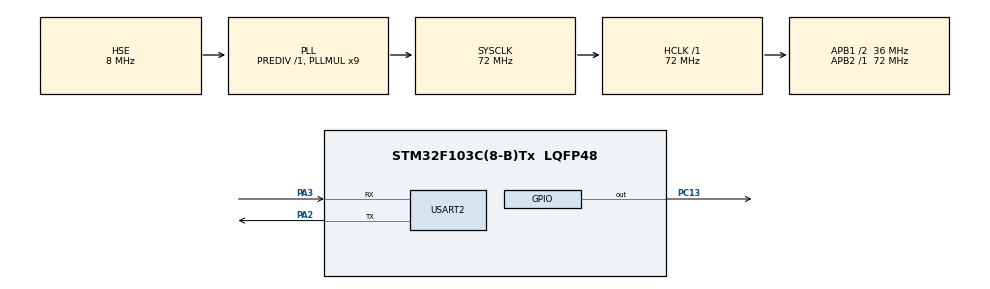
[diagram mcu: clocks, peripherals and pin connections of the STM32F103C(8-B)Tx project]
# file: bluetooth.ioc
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Mcu.Family=STM32F1
Mcu.Name=STM32F103C(8-B)Tx
Mcu.Package=LQFP48
NVIC.PriorityGroup=NVIC_PRIORITYGROUP_4
NVIC.TIM2_IRQn=true\:0\:0\:false\:false\:true\:true\:true\:true
NVIC.USART2_IRQn=true\:0\:0\:false\:false\:true\:true\:true\:true
PA13.Mode=Serial_Wire
PA13.Signal=SYS_JTMS-SWDIO
PA14.Mode=Serial_Wire
PA14.Signal=SYS_JTCK-SWCLK
PA2.Mode=Asynchronous
PA2.Signal=USART2_TX
PA3.Mode=Asynchronous
PA3.Signal=USART2_RX
PC13-TAMPER-RTC.Signal=GPIO_Output
PD0-OSC_IN.Mode=HSE-External-Oscillator
PD0-OSC_IN.Signal=RCC_OSC_IN
PD1-OSC_OUT.Mode=HSE-External-Oscillator
PD1-OSC_OUT.Signal=RCC_OSC_OUT
ProjectManager.HeapSize=0x200
ProjectManager.StackSize=0x400
ProjectManager.TargetToolchain=MDK-ARM V5.32
RCC.AHBFreq_Value=72000000
RCC.APB1CLKDivider=RCC_HCLK_DIV2
RCC.APB1Freq_Value=36000000
RCC.APB1TimFreq_Value=72000000
RCC.APB2Freq_Value=72000000
RCC.APB2TimFreq_Value=72000000
RCC.HCLKFreq_Value=72000000
RCC.PLLMUL=RCC_PLL_MUL9
RCC.PLLSourceVirtual=RCC_PLLSOURCE_HSE
RCC.SYSCLKFreq_VALUE=72000000
RCC.SYSCLKSource=RCC_SYSCLKSOURCE_PLLCLK
RCC.USBFreq_Value=72000000
TIM2.Period=4000
TIM2.Prescaler=35999
TIM2.TIM_MasterOutputTrigger=TIM_TRGO_UPDATE
USART2.VirtualMode=VM_ASYNC
VP_TIM2_VS_ClockSourceINT.Mode=Internal
board=custom

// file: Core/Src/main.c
/* USER CODE BEGIN Header */
/**
  ******************************************************************************
  * @file           : main.c
  * @brief          : Main program body
  ******************************************************************************
  * @attention
  *
  * Copyright (c) 2025 STMicroelectronics.
  * All rights reserved.
  *
  * This software is licensed under terms that can be found in the LICENSE file
  * in the root directory of this software component.
  * If no LICENSE file comes with this software, it is provided AS-IS.
  *
  ******************************************************************************
  */
/* USER CODE END Header */
#include "main.h"

/* USER CODE BEGIN Includes */
#include <string.h>
/* USER CODE END Includes */

TIM_HandleTypeDef htim2;

UART_HandleTypeDef huart2;

/* USER CODE BEGIN PV */
char str1[60] ={0};
typedef struct USART_prop{
	uint8_t usart_buf[60];
	uint8_t usart_cnt;
	uint8_t is_tcp_connect;
	uint8_t is_text;
} USART_prop_ptr;
USART_prop_ptr usartprop;
char *str2[] =
{
	"String1\r\n",
	"String2\r\n",
	"String3\r\n",
	"String4\r\n",
	"String5\r\n"
};
/* USER CODE END PV */

void SystemClock_Config(void);
static void MX_GPIO_Init(void);
static void MX_TIM2_Init(void);
static void MX_USART2_UART_Init(void);

/* USER CODE BEGIN 0 */
void string_parse(char* buf_str){
	HAL_UART_Transmit(&huart2, (uint8_t*)buf_str, strlen(buf_str), 0x1000);
	HAL_GPIO_TogglePin(GPIOA, GPIO_PIN_13);
}
void UART2_RxCpltCallback(void){
	uint8_t b;
	b = str1[0];
	if (usartprop.usart_cnt>59)
	{
		usartprop.usart_cnt=0;

		HAL_UART_Receive_IT(&huart2, (uint8_t*)str1, 1);
		return;
	}
	usartprop.usart_buf[usartprop.usart_cnt] = b;
	if (b==0x0A)
	{
		usartprop.usart_buf[usartprop.usart_cnt+1] = 0;

		string_parse((char*)usartprop.usart_buf);
		usartprop.usart_cnt=0;

		HAL_UART_Receive_IT(&huart2, (uint8_t*)str1, 1);
		return;
	}
	usartprop.usart_cnt++;
	HAL_UART_Receive_IT(&huart2, (uint8_t*)str1, 1);
}
/* USER CODE END 0 */

int main(void)
{

  /* MCU Configuration--------------------------------------------------------*/

  /* Reset of all peripherals, Initializes the Flash interface and the Systick. */
  HAL_Init();

  /* Configure the system clock */
  SystemClock_Config();

  /* Initialize all configured peripherals */
  MX_GPIO_Init();
  MX_TIM2_Init();
  MX_USART2_UART_Init();
  /* USER CODE BEGIN 2 */
HAL_UART_Receive_IT(&huart2, (uint8_t*)str1, 1);
HAL_TIM_Base_Start_IT(&htim2);
  /* USER CODE END 2 */

  /* Infinite loop */
  while (1)
  {

  }
}

void SystemClock_Config(void)
{
  RCC_OscInitTypeDef RCC_OscInitStruct = {0};
  RCC_ClkInitTypeDef RCC_ClkInitStruct = {0};

  /** Initializes the RCC Oscillators according to the specified parameters
  * in the RCC_OscInitTypeDef structure.
  */
  RCC_OscInitStruct.OscillatorType = RCC_OSCILLATORTYPE_HSE;
  RCC_OscInitStruct.HSEState = RCC_HSE_ON;
  RCC_OscInitStruct.HSEPredivValue = RCC_HSE_PREDIV_DIV1;
  RCC_OscInitStruct.HSIState = RCC_HSI_ON;
  RCC_OscInitStruct.PLL.PLLState = RCC_PLL_ON;
  RCC_OscInitStruct.PLL.PLLSource = RCC_PLLSOURCE_HSE;
  RCC_OscInitStruct.PLL.PLLMUL = RCC_PLL_MUL9;
  if (HAL_RCC_OscConfig(&RCC_OscInitStruct) != HAL_OK)
  {
    Error_Handler();
  }

  /** Initializes the CPU, AHB and APB buses clocks
  */
  RCC_ClkInitStruct.ClockType = RCC_CLOCKTYPE_HCLK|RCC_CLOCKTYPE_SYSCLK
                              |RCC_CLOCKTYPE_PCLK1|RCC_CLOCKTYPE_PCLK2;
  RCC_ClkInitStruct.SYSCLKSource = RCC_SYSCLKSOURCE_PLLCLK;
  RCC_ClkInitStruct.AHBCLKDivider = RCC_SYSCLK_DIV1;
  RCC_ClkInitStruct.APB1CLKDivider = RCC_HCLK_DIV2;
  RCC_ClkInitStruct.APB2CLKDivider = RCC_HCLK_DIV1;

  if (HAL_RCC_ClockConfig(&RCC_ClkInitStruct, FLASH_LATENCY_2) != HAL_OK)
  {
    Error_Handler();
  }
}

static void MX_TIM2_Init(void)
{

  TIM_ClockConfigTypeDef sClockSourceConfig = {0};
  TIM_MasterConfigTypeDef sMasterConfig = {0};

  htim2.Instance = TIM2;
  htim2.Init.Prescaler = 35999;
  htim2.Init.CounterMode = TIM_COUNTERMODE_UP;
  htim2.Init.Period = 4000;
  htim2.Init.ClockDivision = TIM_CLOCKDIVISION_DIV1;
  htim2.Init.AutoReloadPreload = TIM_AUTORELOAD_PRELOAD_DISABLE;
  if (HAL_TIM_Base_Init(&htim2) != HAL_OK)
  {
    Error_Handler();
  }
  sClockSourceConfig.ClockSource = TIM_CLOCKSOURCE_INTERNAL;
  if (HAL_TIM_ConfigClockSource(&htim2, &sClockSourceConfig) != HAL_OK)
  {
    Error_Handler();
  }
  sMasterConfig.MasterOutputTrigger = TIM_TRGO_UPDATE;
  sMasterConfig.MasterSlaveMode = TIM_MASTERSLAVEMODE_DISABLE;
  if (HAL_TIMEx_MasterConfigSynchronization(&htim2, &sMasterConfig) != HAL_OK)
  {
    Error_Handler();
  }

}

static void MX_USART2_UART_Init(void)
{

  huart2.Instance = USART2;
  huart2.Init.BaudRate = 115200;
  huart2.Init.WordLength = UART_WORDLENGTH_8B;
  huart2.Init.StopBits = UART_STOPBITS_1;
  huart2.Init.Parity = UART_PARITY_NONE;
  huart2.Init.Mode = UART_MODE_TX_RX;
  huart2.Init.HwFlowCtl = UART_HWCONTROL_NONE;
  huart2.Init.OverSampling = UART_OVERSAMPLING_16;
  if (HAL_UART_Init(&huart2) != HAL_OK)
  {
    Error_Handler();
  }

}

static void MX_GPIO_Init(void)
{
  GPIO_InitTypeDef GPIO_InitStruct = {0};

  /* GPIO Ports Clock Enable */
  __HAL_RCC_GPIOC_CLK_ENABLE();
  __HAL_RCC_GPIOD_CLK_ENABLE();
  __HAL_RCC_GPIOA_CLK_ENABLE();

  /*Configure GPIO pin Output Level */
  HAL_GPIO_WritePin(GPIOC, GPIO_PIN_13, GPIO_PIN_RESET);

  /*Configure GPIO pin : PC13 */
  GPIO_InitStruct.Pin = GPIO_PIN_13;
  GPIO_InitStruct.Mode = GPIO_MODE_OUTPUT_PP;
  GPIO_InitStruct.Pull = GPIO_NOPULL;
  GPIO_InitStruct.Speed = GPIO_SPEED_FREQ_LOW;
  HAL_GPIO_Init(GPIOC, &GPIO_InitStruct);

}

/* USER CODE BEGIN 4 */
void HAL_UART_RxCpltCallback(UART_HandleTypeDef *huart)
{
	if (huart == &huart2)
	{
		UART2_RxCpltCallback();
	}
}
/* USER CODE END 4 */

void Error_Handler(void)
{
  __disable_irq();
  while (1)
  {
  }
}
